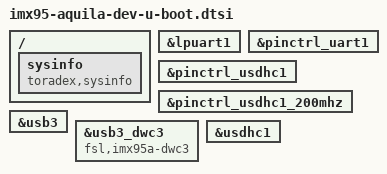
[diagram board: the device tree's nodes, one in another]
// SPDX-License-Identifier: GPL-2.0-or-later OR MIT
/* Copyright (c) Toradex */

#include "imx95-u-boot.dtsi"

/ {
	sysinfo {
		compatible = "toradex,sysinfo";
	};
};

&lpuart1 {
	bootph-pre-ram;
};

&pinctrl_uart1 {
	bootph-pre-ram;
};

&pinctrl_usdhc1 {
	bootph-pre-ram;
};

&pinctrl_usdhc1_200mhz {
	bootph-pre-ram;
};

&usb3 {
	bootph-pre-ram;
};

&usb3_dwc3 {
	bootph-pre-ram;
	compatible = "fsl,imx95a-dwc3", "fsl,imx8mq-dwc3", "snps,dwc3";
};

&usdhc1 {
	bootph-pre-ram;
};

